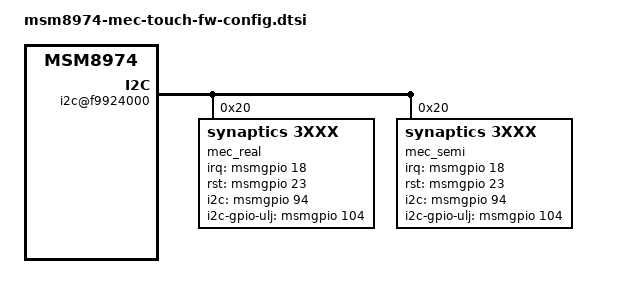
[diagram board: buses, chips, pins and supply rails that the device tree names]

/* Copyright (c) 2013, The Linux Foundation. All rights reserved.
 *
 * This program is free software; you can redistribute it and/or modify
 * it under the terms of the GNU General Public License version 2 and
 * only version 2 as published by the Free Software Foundation.
 *
 * This program is distributed in the hope that it will be useful,
 * but WITHOUT ANY WARRANTY; without even the implied warranty of
 * MERCHANTABILITY or FITNESS FOR A PARTICULAR PURPOSE.  See the
 * GNU General Public License for more details.
 */

&soc {
	i2c@f9924000 {
		mec_real@20 {
			compatible               = "synaptics,3xxx";
			reg                      = <0x20>;
			interrupt-parent         = <&msmgpio>;
			interrupts               = <18 0x2>;
			synaptics,display-coords = <0 1080 0 1920>;
			synaptics,irq-gpio       = <&msmgpio 18 0x00>;
			synaptics,rst-gpio       = <&msmgpio 23 0x00>;
			synaptics,i2c-gpio       = <&msmgpio 94 0x00>;
			synaptics,i2c-gpio-ulj   = <&msmgpio 104 0x00>;
			synaptics,i2c_err_hlr    = <1>;
			tw_pin_mask              = <0x05>;
			report_type              = <1>;
			virtualkey0              = <&syn_vk>;
			virtualkey1              = <&syn_vk_1>;
			virtualkey2              = <&syn_vk_t6>;

			config_3508_0key_metmm_1 {
				default_cfg   = <1>;
				pr_number     = <1606383>;
				sensor_id     = <0x0>;
				syn,pl-coords = <0 1620 0 2880>;
				vkey_setting  = <0>;
				config = [
					4D 45 43 01 00 3F 03 1E
					05 0E 54 06 40 0B 08 43
					87 41 00 00 00 00 0F 1B
					01 1E 05 EF 32 E0 02 28
					10 02 11 01 E7 BD DC C5
					89 80 C4 C4 05 03 12 1E
					8C 0F 0A 20 00 01 01 07
					04 04 0A C0 19 64 26 26
					80 80 00 00 1E 03 06 14
					28 10 40 10 04 04 57 1C
					00 15 40 32 50 00 00 00
					00 4C 04 6C 07 3C 32 00
					00 00 00 4C 04 6C 07 1E
					05 1E 04 0A 04 0A 00 0A
					04 04 00 00 00 01 05 0A
					10 00 00 00 14 03 06 0F
					0A 00 4B 00 FF 00 06 01
					80 04 1B 00 00 00 64 00
					00 00 BE 4B 96 00 00 C0
					80 00 10 0A 18 00 7D 00
					02 00 00 90 01 02 00 03
					03 07 07 03 96 00 08 0C
					01 04 04 39 00 19 00 00
					00 02 00 01 29 84 37 00
					18 00 01 00 02 00 01 2A
					04 36 00 17 00 02 00 02
					00 01 2B 84 35 00 17 00
					03 00 02 00 01 2C 04 34
					00 17 00 04 00 02 00 01
					2D 83 33 00 16 00 05 00
					05 00 02 26 83 32 00 16
					00 06 00 05 00 02 27 03
					31 00 15 00 07 00 05 00
					02 28 08 08 08 08 08 08
					08 08 08 08 08 08 08 08
					08 00 00 00 00 00 00 00
					00 00 00 00 00 00 00 00
					00 00 00 00 00 00 00 00
					00 00 00 00 00 00 00 00
					00 00 00 00 00 00 00 00
					00 00 00 00 00 00 00 00
					00 00 00 00 00 00 00 00
					00 00 00 00 00 00 0F 0F
					06 00 07 0F 0F 06 00 07
					1D 00 05 00 A6 00 14 64
					05 00 00 07 07 00 00 07
					07 00 1B 28 05 01 00 22
					20 00 05 00 00 02 23 2D
					2D A0 00 A0 00 00 00 00
					00 00 00 00 00 00 00 00
					00 00 FF FF FF FF FF FF
					FF FF 51 51 51 51 CD 0D
					04 83 10 10 10 10 05 20
					1F 1E 1D 1C 1B 1A 18 17
					16 15 14 13 12 11 FF FF
					FF FF FF FF FF 00 01 02
					03 04 05 06 07 08 09 0A
					0B 0C 0D 33 32 31 30 2F
					2E 2D 2C 2B 2A 29 28 27
					FF FF FF FF FF 00 10 00
					10 00 10 00 10 80 80 80
					80 80 80 80 80 80 80 80
					80 80 80 80 80 80 80 80
					80 80 80 80 80 80 80 80
					80 80 80 80 80 80 80 80
					80 80 80 80 80 80 80 80
					80 80 80 80 80 80 80 80
					80 80 80 00 10 00 10 00
					10 00 10 00 00 21 22 FF
					FF 0E 26 35 FF
					];
			};

			config_3508_0key_metss_1 {
				default_cfg   = <1>;
				pr_number     = <1606383>;
				sensor_id     = <0x1>;
				syn,pl-coords = <0 1620 0 2880>;
				vkey_setting  = <0>;
				config = [
					4D 45 43 01 00 3F 03 1E
					05 0E 54 06 40 0B 08 43
					87 41 00 00 00 00 0F 1B
					01 1E 05 EF 32 E0 02 28
					10 02 11 01 E7 BD DC C5
					89 80 C4 C4 05 03 12 1E
					8C 0F 0A 20 00 01 01 07
					04 04 0A C0 19 64 26 26
					80 80 00 00 1E 03 06 14
					28 10 40 10 04 04 57 1C
					00 15 40 32 50 00 00 00
					00 4C 04 6C 07 3C 32 00
					00 00 00 4C 04 6C 07 1E
					05 1E 04 0A 04 0A 00 0A
					04 04 00 00 00 01 05 0A
					10 00 00 00 14 03 06 0F
					0A 00 4B 00 FF 00 06 01
					80 04 1B 00 00 00 64 00
					00 00 BE 4B 96 00 00 C0
					80 00 10 0A 18 00 7D 00
					02 00 00 90 01 02 00 03
					03 07 07 03 96 00 08 0C
					01 04 04 39 00 19 00 00
					00 02 00 01 29 84 37 00
					18 00 01 00 02 00 01 2A
					04 36 00 17 00 02 00 02
					00 01 2B 84 35 00 17 00
					03 00 02 00 01 2C 04 34
					00 17 00 04 00 02 00 01
					2D 83 33 00 16 00 05 00
					05 00 02 26 83 32 00 16
					00 06 00 05 00 02 27 03
					31 00 15 00 07 00 05 00
					02 28 08 08 08 08 08 08
					08 08 08 08 08 08 08 08
					08 00 00 00 00 00 00 00
					00 00 00 00 00 00 00 00
					00 00 00 00 00 00 00 00
					00 00 00 00 00 00 00 00
					00 00 00 00 00 00 00 00
					00 00 00 00 00 00 00 00
					00 00 00 00 00 00 00 00
					00 00 00 00 00 00 0F 0F
					06 00 07 0F 0F 06 00 07
					1D 00 05 00 A6 00 14 64
					05 00 00 07 07 00 00 07
					07 00 1B 28 05 01 00 22
					20 00 05 00 00 02 23 2D
					2D A0 00 A0 00 00 00 00
					00 00 00 00 00 00 00 00
					00 00 FF FF FF FF FF FF
					FF FF 51 51 51 51 CD 0D
					04 83 10 10 10 10 05 20
					1F 1E 1D 1C 1B 1A 18 17
					16 15 14 13 12 11 FF FF
					FF FF FF FF FF 00 01 02
					03 04 05 06 07 08 09 0A
					0B 0C 0D 33 32 31 30 2F
					2E 2D 2C 2B 2A 29 28 27
					FF FF FF FF FF 00 10 00
					10 00 10 00 10 80 80 80
					80 80 80 80 80 80 80 80
					80 80 80 80 80 80 80 80
					80 80 80 80 80 80 80 80
					80 80 80 80 80 80 80 80
					80 80 80 80 80 80 80 80
					80 80 80 80 80 80 80 80
					80 80 80 00 10 00 10 00
					10 00 10 00 00 21 22 FF
					FF 0E 26 35 FF
					];
			};



			config_3508_0key_metm_1 {
				default_cfg   = <1>;
				pr_number     = <1582320>;
				sensor_id     = <0x0>;
				syn,pl-coords = <0 1620 0 2880>;
				vkey_setting  = <0>;
				config = [
					4D 45 43 01 00 3F 03 1E
					05 0E 54 06 40 0B 08 43
					87 41 00 00 00 00 0F 1B
					01 1E 05 EF 32 E0 02 28
					10 02 11 01 E7 BD DC C5
					89 80 C4 C4 05 03 12 1E
					8C 0F 0A 20 00 01 01 07
					04 04 0A C0 19 64 26 26
					80 80 00 00 1E 03 06 14
					28 10 40 10 04 04 57 1C
					00 15 40 32 50 00 00 00
					00 4C 04 6C 07 3C 32 00
					00 00 00 4C 04 6C 07 1E
					05 1E 04 0A 04 0A 00 0A
					04 04 00 00 00 01 05 0A
					10 00 00 00 14 03 06 0F
					0A 00 4B 00 FF 00 06 01
					80 04 1B 00 00 00 64 00
					00 00 BE 4B 96 00 00 C0
					80 00 10 0A 18 00 7D 00
					02 00 00 90 01 02 00 03
					03 07 07 03 96 00 08 0C
					01 04 04 39 00 19 00 00
					00 02 00 01 29 84 37 00
					18 00 01 00 02 00 01 2A
					04 36 00 17 00 02 00 02
					00 01 2B 84 35 00 17 00
					03 00 02 00 01 2C 04 34
					00 17 00 04 00 02 00 01
					2D 83 33 00 16 00 05 00
					05 00 02 26 83 32 00 16
					00 06 00 05 00 02 27 03
					31 00 15 00 07 00 05 00
					02 28 08 08 08 08 08 08
					08 08 08 08 08 08 08 08
					08 00 00 00 00 00 00 00
					00 00 00 00 00 00 00 00
					00 00 00 00 00 00 00 00
					00 00 00 00 00 00 00 00
					00 00 00 00 00 00 00 00
					00 00 00 00 00 00 00 00
					00 00 00 00 00 00 00 00
					00 00 00 00 00 00 0F 0F
					06 00 07 0F 0F 06 00 07
					1D 00 05 00 A6 00 14 64
					05 00 00 07 07 00 00 07
					07 00 1B 28 05 01 00 22
					20 00 05 00 00 02 23 2D
					2D A0 00 A0 00 00 00 00
					00 00 00 00 00 00 00 00
					00 00 FF FF FF FF FF FF
					FF FF 51 51 51 51 CD 0D
					04 83 10 10 10 10 05 20
					1F 1E 1D 1C 1B 1A 18 17
					16 15 14 13 12 11 FF FF
					FF FF FF FF FF 00 01 02
					03 04 05 06 07 08 09 0A
					0B 0C 0D 33 32 31 30 2F
					2E 2D 2C 2B 2A 29 28 27
					FF FF FF FF FF 00 10 00
					10 00 10 00 10 80 80 80
					80 80 80 80 80 80 80 80
					80 80 80 80 80 80 80 80
					80 80 80 80 80 80 80 80
					80 80 80 80 80 80 80 80
					80 80 80 80 80 80 80 80
					80 80 80 80 80 80 80 80
					80 80 80 00 10 00 10 00
					10 00 10 00 00 21 22 FF
					FF 0E 26 35 FF
				];
			};

			config_3508_0key_mets_1 {
				default_cfg   = <1>;
				pr_number     = <1582320>;
				sensor_id     = <0x1>;
				syn,pl-coords = <0 1620 0 2880>;
				vkey_setting  = <0>;
				config = [
					4D 45 43 01 00 3F 03 1E
					05 0E 54 06 40 0B 08 43
					87 41 00 00 00 00 0F 1B
					01 1E 05 EF 32 E0 02 28
					10 02 11 01 E7 BD DC C5
					89 80 C4 C4 05 03 12 1E
					8C 0F 0A 20 00 01 01 07
					04 04 0A C0 19 64 26 26
					80 80 00 00 1E 03 06 14
					28 10 40 10 04 04 57 1C
					00 15 40 32 50 00 00 00
					00 4C 04 6C 07 3C 32 00
					00 00 00 4C 04 6C 07 1E
					05 1E 04 0A 04 0A 00 0A
					04 04 00 00 00 01 05 0A
					10 00 00 00 14 03 06 0F
					0A 00 4B 00 FF 00 06 01
					80 04 1B 00 00 00 64 00
					00 00 BE 4B 96 00 00 C0
					80 00 10 0A 18 00 7D 00
					02 00 00 90 01 02 00 03
					03 07 07 03 96 00 08 0C
					01 04 04 39 00 19 00 00
					00 02 00 01 29 84 37 00
					18 00 01 00 02 00 01 2A
					04 36 00 17 00 02 00 02
					00 01 2B 84 35 00 17 00
					03 00 02 00 01 2C 04 34
					00 17 00 04 00 02 00 01
					2D 83 33 00 16 00 05 00
					05 00 02 26 83 32 00 16
					00 06 00 05 00 02 27 03
					31 00 15 00 07 00 05 00
					02 28 08 08 08 08 08 08
					08 08 08 08 08 08 08 08
					08 00 00 00 00 00 00 00
					00 00 00 00 00 00 00 00
					00 00 00 00 00 00 00 00
					00 00 00 00 00 00 00 00
					00 00 00 00 00 00 00 00
					00 00 00 00 00 00 00 00
					00 00 00 00 00 00 00 00
					00 00 00 00 00 00 0F 0F
					06 00 07 0F 0F 06 00 07
					1D 00 05 00 A6 00 14 64
					05 00 00 07 07 00 00 07
					07 00 1B 28 05 01 00 22
					20 00 05 00 00 02 23 2D
					2D A0 00 A0 00 00 00 00
					00 00 00 00 00 00 00 00
					00 00 FF FF FF FF FF FF
					FF FF 51 51 51 51 CD 0D
					04 83 10 10 10 10 05 20
					1F 1E 1D 1C 1B 1A 18 17
					16 15 14 13 12 11 FF FF
					FF FF FF FF FF 00 01 02
					03 04 05 06 07 08 09 0A
					0B 0C 0D 33 32 31 30 2F
					2E 2D 2C 2B 2A 29 28 27
					FF FF FF FF FF 00 10 00
					10 00 10 00 10 80 80 80
					80 80 80 80 80 80 80 80
					80 80 80 80 80 80 80 80
					80 80 80 80 80 80 80 80
					80 80 80 80 80 80 80 80
					80 80 80 80 80 80 80 80
					80 80 80 80 80 80 80 80
					80 80 80 00 10 00 10 00
					10 00 10 00 00 21 22 FF
					FF 0E 26 35 FF
				];
			};

			config_3508_0key_tsxm_2 {
				default_cfg   = <1>;
				pr_number     = <1543518>;
				sensor_id     = <0x4>;
				syn,pl-coords = <0 1620 0 2880>;
				vkey_setting  = <0>;
				config = [
					54 53 58 00 00 3F 03 1E
					05 0E 54 06 40 0B 4D 41
					48 3B 00 00 00 00 11 1B
					01 1E 05 EF 32 E0 02 28
					19 01 1D 00 48 C9 05 E4
					89 80 C4 C4 05 03 12 1E
					5A 0F 0A 20 00 01 01 07
					04 04 0A C0 19 64 26 26
					80 80 00 00 1E 03 06 14
					28 10 40 10 04 04 2D 1C
					00 15 40 32 50 00 00 00
					00 4C 04 6C 07 3C 32 00
					00 00 00 4C 04 6C 07 1E
					05 1E 04 0A 04 0A 00 0A
					04 04 00 00 00 01 05 0A
					10 00 00 00 14 03 06 0F
					0A 00 4B 00 FF 00 04 01
					80 04 1B 00 00 00 64 00
					00 00 BE 4B 96 00 00 C0
					80 00 10 0A 18 00 7D 00
					02 00 00 90 01 02 00 06
					06 07 07 00 96 00 08 0C
					01 04 03 2A 00 13 00 00
					00 03 00 01 25 03 29 00
					12 00 02 00 03 00 01 27
					03 28 00 11 00 04 00 03
					00 01 28 02 26 00 11 00
					06 00 03 00 01 29 02 25
					00 10 00 08 00 07 00 02
					25 02 24 00 10 00 0A 00
					07 00 02 26 02 23 00 0F
					00 0C 00 07 00 02 27 02
					22 00 0F 00 0E 00 04 00
					01 23 0F 0F 0F 0F 0F 0F
					0F 0F 0F 0F 0F 0F 0F 0F
					0F 0F 00 00 00 00 00 00
					00 00 00 00 00 00 00 00
					00 00 00 00 00 00 00 00
					00 00 00 00 00 00 00 00
					00 00 00 00 00 00 00 00
					00 00 00 00 00 00 00 00
					00 00 00 00 00 00 00 00
					00 00 00 00 00 00 0E 0E
					02 00 04 0E 0E 02 00 04
					2B 00 05 00 A6 00 14 64
					05 04 04 03 03 04 04 03
					03 00 1B 28 05 01 00 22
					20 00 05 00 00 00 14 28
					28 A0 00 A0 00 00 00 00
					00 00 00 00 00 00 00 00
					00 00 FF FF FF FF FF FF
					FF FF 51 51 51 51 CD 0D
					04 83 10 10 10 10 05 22
					21 20 1F 1E 1D 1C 1B 1A
					19 18 17 16 15 14 13 12
					FF FF FF FF FF 00 01 02
					03 04 05 06 07 08 09 0A
					0B 0C 0D 0E 26 33 32 31
					30 2F 2E 2D 2C 2B 2A 29
					FF FF FF FF FF 00 10 00
					10 00 10 00 10 80 80 80
					80 80 80 80 80 80 80 80
					80 80 80 80 80 80 80 80
					80 80 80 80 80 80 80 80
					80 80 80 80 80 80 80 80
					80 80 80 80 80 80 80 80
					80 80 80 80 80 80 80 80
					80 80 80 00 10 00 10 00
					10 00 10 00 00 FF FF FF
					FF FF FF FF FF
				];
			};

			config_3508_0key_tsms_2 {
				default_cfg   = <1>;
				pr_number     = <1543518>;
				sensor_id     = <0x5>;
				syn,pl-coords = <0 1620 0 2880>;
				vkey_setting  = <0>;
				config = [
					54 53 58 00 00 3F 03 1E
					05 0E 54 06 40 0B 4D 41
					48 3B 00 00 00 00 11 1B
					01 1E 05 EF 32 E0 02 28
					19 01 1D 00 48 C9 05 E4
					89 80 C4 C4 05 03 12 1E
					5A 0F 0A 20 00 01 01 07
					04 04 0A C0 19 64 26 26
					80 80 00 00 1E 03 06 14
					28 10 40 10 04 04 2D 1C
					00 15 40 32 50 00 00 00
					00 4C 04 6C 07 3C 32 00
					00 00 00 4C 04 6C 07 1E
					05 1E 04 0A 04 0A 00 0A
					04 04 00 00 00 01 05 0A
					10 00 00 00 14 03 06 0F
					0A 00 4B 00 FF 00 04 01
					80 04 1B 00 00 00 64 00
					00 00 BE 4B 96 00 00 C0
					80 00 10 0A 18 00 7D 00
					02 00 00 90 01 02 00 06
					06 07 07 00 96 00 08 0C
					01 04 03 2A 00 13 00 00
					00 03 00 01 25 03 29 00
					12 00 02 00 03 00 01 27
					03 28 00 11 00 04 00 03
					00 01 28 02 26 00 11 00
					06 00 03 00 01 29 02 25
					00 10 00 08 00 07 00 02
					25 02 24 00 10 00 0A 00
					07 00 02 26 02 23 00 0F
					00 0C 00 07 00 02 27 02
					22 00 0F 00 0E 00 04 00
					01 23 0F 0F 0F 0F 0F 0F
					0F 0F 0F 0F 0F 0F 0F 0F
					0F 0F 00 00 00 00 00 00
					00 00 00 00 00 00 00 00
					00 00 00 00 00 00 00 00
					00 00 00 00 00 00 00 00
					00 00 00 00 00 00 00 00
					00 00 00 00 00 00 00 00
					00 00 00 00 00 00 00 00
					00 00 00 00 00 00 0E 0E
					02 00 04 0E 0E 02 00 04
					2B 00 05 00 A6 00 14 64
					05 04 04 03 03 04 04 03
					03 00 1B 28 05 01 00 22
					20 00 05 00 00 00 14 28
					28 A0 00 A0 00 00 00 00
					00 00 00 00 00 00 00 00
					00 00 FF FF FF FF FF FF
					FF FF 51 51 51 51 CD 0D
					04 83 10 10 10 10 05 22
					21 20 1F 1E 1D 1C 1B 1A
					19 18 17 16 15 14 13 12
					FF FF FF FF FF 00 01 02
					03 04 05 06 07 08 09 0A
					0B 0C 0D 0E 26 33 32 31
					30 2F 2E 2D 2C 2B 2A 29
					FF FF FF FF FF 00 10 00
					10 00 10 00 10 80 80 80
					80 80 80 80 80 80 80 80
					80 80 80 80 80 80 80 80
					80 80 80 80 80 80 80 80
					80 80 80 80 80 80 80 80
					80 80 80 80 80 80 80 80
					80 80 80 80 80 80 80 80
					80 80 80 00 10 00 10 00
					10 00 10 00 00 FF FF FF
					FF FF FF FF FF
				];
			};

			config_3508_2key_metm_1 {
				default_cfg   = <1>;
				pr_number     = <1543518>;
				sensor_id     = <0x0>;
				syn,pl-coords = <0 1620 0 2880>;
				vkey_setting  = <0>;
				config = [
					4D 45 54 31 00 3F 03 1E
					05 0E 54 06 40 0B 23 43
					5A 41 00 00 00 00 0F 1B
					01 1E 05 EF 32 DD 02 50
					19 01 1D 00 48 C9 05 E4
					89 80 C4 C4 05 03 12 1E
					5A 0F 0A 20 00 01 01 07
					04 04 0A C0 19 64 26 26
					80 80 00 00 1E 03 06 14
					28 10 40 10 04 04 2D 1C
					00 15 40 32 50 32 00 00
					00 00 4C 04 6C 07 3C 32
					00 00 00 00 4C 04 6C 07
					1E 05 1E 04 0A 04 0A 00
					0A 04 04 00 00 00 01 05
					0A 00 00 00 4B FF 00 04
					01 80 04 1B 00 00 00 64
					00 00 00 BE 4B 96 00 00
					C0 80 00 10 0A 18 00 7D
					00 02 00 00 90 01 02 00
					06 06 07 07 00 96 00 08
					0C 01 04 03 29 00 13 00
					00 00 03 00 01 25 03 28
					00 12 00 02 00 03 00 01
					27 82 26 00 11 00 04 00
					03 00 01 28 02 25 00 11
					00 06 00 03 00 01 29 02
					24 00 10 00 08 00 07 00
					02 25 02 23 00 10 00 0A
					00 07 00 02 26 02 22 00
					0F 00 0C 00 07 00 02 27
					02 21 00 0F 00 0E 00 04
					00 01 23 0E 0F 0F 0F 0F
					0F 0E 0F 0F 0F 0F 0F 0F
					0F 0F 0F 0C 00 00 00 00
					00 00 00 00 00 00 00 00
					00 00 00 00 00 00 00 00
					00 00 00 00 00 00 00 00
					00 00 00 00 00 00 00 00
					00 00 00 00 00 00 00 00
					00 00 00 00 00 00 00 00
					00 00 00 00 00 00 00 0E
					0E 02 00 04 0E 0E 02 00
					04 2B 00 05 00 A6 00 14
					64 05 04 04 03 03 04 04
					03 03 00 1B 28 05 01 00
					22 20 00 05 00 00 00 14
					2D 2D A0 00 A0 00 00 00
					00 FF FF FF FF FF FF FF
					FF A1 A1 51 51 CD 0D 04
					83 10 10 10 10 05 1F 1E
					1D 1C 1B 1A 19 18 17 16
					15 14 13 12 11 FF FF FF
					FF FF FF FF 00 01 02 03
					04 05 06 07 08 09 0A 0B
					0C 0D 33 32 31 30 2F 2E
					2D 2C 2B 2A 29 28 27 FF
					FF FF FF FF 00 10 00 10
					00 10 00 10 80 80 80 80
					80 80 80 80 80 80 80 80
					80 80 80 80 80 80 80 80
					80 80 80 80 80 80 80 80
					80 80 80 80 80 80 80 80
					80 80 80 80 80 80 80 80
					80 80 80 80 80 80 80 80
					80 80 00 10 00 10 00 10
					00 10
				];
			};

			config_3508_2key_mets_1 {
				default_cfg   = <1>;
				pr_number     = <1543518>;
				sensor_id     = <0x1>;
				syn,pl-coords = <0 1620 0 2880>;
				vkey_setting  = <0>;
				config = [
					4D 45 54 31 00 3F 03 1E
					05 0E 54 06 40 0B 23 43
					5A 41 00 00 00 00 0F 1B
					01 1E 05 EF 32 DD 02 50
					19 01 1D 00 48 C9 05 E4
					89 80 C4 C4 05 03 12 1E
					5A 0F 0A 20 00 01 01 07
					04 04 0A C0 19 64 26 26
					80 80 00 00 1E 03 06 14
					28 10 40 10 04 04 2D 1C
					00 15 40 32 50 32 00 00
					00 00 4C 04 6C 07 3C 32
					00 00 00 00 4C 04 6C 07
					1E 05 1E 04 0A 04 0A 00
					0A 04 04 00 00 00 01 05
					0A 00 00 00 4B FF 00 04
					01 80 04 1B 00 00 00 64
					00 00 00 BE 4B 96 00 00
					C0 80 00 10 0A 18 00 7D
					00 02 00 00 90 01 02 00
					06 06 07 07 00 96 00 08
					0C 01 04 03 29 00 13 00
					00 00 03 00 01 25 03 28
					00 12 00 02 00 03 00 01
					27 82 26 00 11 00 04 00
					03 00 01 28 02 25 00 11
					00 06 00 03 00 01 29 02
					24 00 10 00 08 00 07 00
					02 25 02 23 00 10 00 0A
					00 07 00 02 26 02 22 00
					0F 00 0C 00 07 00 02 27
					02 21 00 0F 00 0E 00 04
					00 01 23 0E 0F 0F 0F 0F
					0F 0E 0F 0F 0F 0F 0F 0F
					0F 0F 0F 0C 00 00 00 00
					00 00 00 00 00 00 00 00
					00 00 00 00 00 00 00 00
					00 00 00 00 00 00 00 00
					00 00 00 00 00 00 00 00
					00 00 00 00 00 00 00 00
					00 00 00 00 00 00 00 00
					00 00 00 00 00 00 00 0E
					0E 02 00 04 0E 0E 02 00
					04 2B 00 05 00 A6 00 14
					64 05 04 04 03 03 04 04
					03 03 00 1B 28 05 01 00
					22 20 00 05 00 00 00 14
					2D 2D A0 00 A0 00 00 00
					00 FF FF FF FF FF FF FF
					FF A1 A1 51 51 CD 0D 04
					83 10 10 10 10 05 1F 1E
					1D 1C 1B 1A 19 18 17 16
					15 14 13 12 11 FF FF FF
					FF FF FF FF 00 01 02 03
					04 05 06 07 08 09 0A 0B
					0C 0D 33 32 31 30 2F 2E
					2D 2C 2B 2A 29 28 27 FF
					FF FF FF FF 00 10 00 10
					00 10 00 10 80 80 80 80
					80 80 80 80 80 80 80 80
					80 80 80 80 80 80 80 80
					80 80 80 80 80 80 80 80
					80 80 80 80 80 80 80 80
					80 80 80 80 80 80 80 80
					80 80 80 80 80 80 80 80
					80 80 00 10 00 10 00 10
					00 10
				];
			};

			config_3508_0key_tsxm_1 {
				default_cfg   = <1>;
				pr_number     = <1543518>;
				sensor_id     = <0x4>;
				syn,pl-coords = <0 1620 0 2880>;
				vkey_setting  = <0>;
				config = [
					54 53 58 31 00 3F 03 1E
					05 0E 54 06 40 0B 48 3B
					66 41 00 00 00 00 11 1B
					01 1E 05 EF 32 DD 02 50
					19 01 1D 00 48 C9 05 E4
					89 80 C4 C4 05 03 12 1E
					5A 0F 0A 20 00 01 01 07
					04 04 0A C0 19 64 26 26
					80 80 00 00 1E 03 06 14
					28 10 40 10 04 04 2D 1C
					00 15 40 32 50 32 00 00
					00 00 4C 04 6C 07 3C 32
					00 00 00 00 4C 04 6C 07
					1E 05 1E 04 0A 04 0A 00
					0A 04 04 00 00 00 01 05
					0A 00 00 00 4B FF 00 04
					01 80 04 1B 00 00 00 64
					00 00 00 BE 4B 96 00 00
					C0 80 00 10 0A 18 00 7D
					00 02 00 00 90 01 02 00
					06 06 07 07 00 96 00 08
					0C 01 04 03 29 00 13 00
					00 00 03 00 01 25 03 28
					00 12 00 02 00 03 00 01
					27 82 26 00 11 00 04 00
					03 00 01 28 02 25 00 11
					00 06 00 03 00 01 29 02
					24 00 10 00 08 00 07 00
					02 25 02 23 00 10 00 0A
					00 07 00 02 26 02 22 00
					0F 00 0C 00 07 00 02 27
					02 21 00 0F 00 0E 00 04
					00 01 23 0E 0F 0F 0F 0F
					0F 0E 0F 0F 0F 0F 0F 0F
					0F 0F 0F 0C 00 00 00 00
					00 00 00 00 00 00 00 00
					00 00 00 00 00 00 00 00
					00 00 00 00 00 00 00 00
					00 00 00 00 00 00 00 00
					00 00 00 00 00 00 00 00
					00 00 00 00 00 00 00 00
					00 00 00 00 00 00 00 0E
					0E 02 00 04 0E 0E 02 00
					04 2B 00 05 00 A6 00 14
					64 05 04 04 03 03 04 04
					03 03 00 1B 28 05 01 00
					22 20 00 05 00 00 00 14
					2D 2D A0 00 A0 00 00 00
					00 FF FF FF FF FF FF FF
					FF A1 A1 51 51 CD 0D 04
					83 10 10 10 10 05 22 21
					20 1F 1E 1D 1C 1B 1A 19
					18 17 16 15 14 13 12 FF
					FF FF FF FF 00 01 02 03
					04 05 06 07 08 09 0A 0B
					0C 0D 0E 26 33 32 31 30
					2F 2E 2D 2C 2B 2A 29 FF
					FF FF FF FF 00 10 00 10
					00 10 00 10 80 80 80 80
					80 80 80 80 80 80 80 80
					80 80 80 80 80 80 80 80
					80 80 80 80 80 80 80 80
					80 80 80 80 80 80 80 80
					80 80 80 80 80 80 80 80
					80 80 80 80 80 80 80 80
					80 80 00 10 00 10 00 10
					00 10
				];
			};

			config_3508_0key_tsms_1 {
				default_cfg   = <1>;
				pr_number     = <1543518>;
				sensor_id     = <0x5>;
				syn,pl-coords = <0 1620 0 2880>;
				vkey_setting  = <0>;
				config = [
					54 53 58 31 00 3F 03 1E
					05 0E 54 06 40 0B 48 3B
					66 41 00 00 00 00 11 1B
					01 1E 05 EF 32 DD 02 50
					19 01 1D 00 48 C9 05 E4
					89 80 C4 C4 05 03 12 1E
					5A 0F 0A 20 00 01 01 07
					04 04 0A C0 19 64 26 26
					80 80 00 00 1E 03 06 14
					28 10 40 10 04 04 2D 1C
					00 15 40 32 50 32 00 00
					00 00 4C 04 6C 07 3C 32
					00 00 00 00 4C 04 6C 07
					1E 05 1E 04 0A 04 0A 00
					0A 04 04 00 00 00 01 05
					0A 00 00 00 4B FF 00 04
					01 80 04 1B 00 00 00 64
					00 00 00 BE 4B 96 00 00
					C0 80 00 10 0A 18 00 7D
					00 02 00 00 90 01 02 00
					06 06 07 07 00 96 00 08
					0C 01 04 03 29 00 13 00
					00 00 03 00 01 25 03 28
					00 12 00 02 00 03 00 01
					27 82 26 00 11 00 04 00
					03 00 01 28 02 25 00 11
					00 06 00 03 00 01 29 02
					24 00 10 00 08 00 07 00
					02 25 02 23 00 10 00 0A
					00 07 00 02 26 02 22 00
					0F 00 0C 00 07 00 02 27
					02 21 00 0F 00 0E 00 04
					00 01 23 0E 0F 0F 0F 0F
					0F 0E 0F 0F 0F 0F 0F 0F
					0F 0F 0F 0C 00 00 00 00
					00 00 00 00 00 00 00 00
					00 00 00 00 00 00 00 00
					00 00 00 00 00 00 00 00
					00 00 00 00 00 00 00 00
					00 00 00 00 00 00 00 00
					00 00 00 00 00 00 00 00
					00 00 00 00 00 00 00 0E
					0E 02 00 04 0E 0E 02 00
					04 2B 00 05 00 A6 00 14
					64 05 04 04 03 03 04 04
					03 03 00 1B 28 05 01 00
					22 20 00 05 00 00 00 14
					2D 2D A0 00 A0 00 00 00
					00 FF FF FF FF FF FF FF
					FF A1 A1 51 51 CD 0D 04
					83 10 10 10 10 05 22 21
					20 1F 1E 1D 1C 1B 1A 19
					18 17 16 15 14 13 12 FF
					FF FF FF FF 00 01 02 03
					04 05 06 07 08 09 0A 0B
					0C 0D 0E 26 33 32 31 30
					2F 2E 2D 2C 2B 2A 29 FF
					FF FF FF FF 00 10 00 10
					00 10 00 10 80 80 80 80
					80 80 80 80 80 80 80 80
					80 80 80 80 80 80 80 80
					80 80 80 80 80 80 80 80
					80 80 80 80 80 80 80 80
					80 80 80 80 80 80 80 80
					80 80 80 80 80 80 80 80
					80 80 00 10 00 10 00 10
					00 10
				];
			};

			config_t6m_1 {
				default_cfg   = <1>;
				pr_number     = <1501819>;
				sensor_id     = <0x04>;
				syn,pl-coords = <50 1050 0 1800>;
				vkey_setting  = <2>;
				config = [
					00 00 00 02 04 3F 03 1E
					05 0E 4C 04 6C 07 00 40
					00 40 00 00 00 00 11 1D
					01 1E 05 F5 28 1E 05 28
					30 00 30 00 F0 D2 F0 D2
					89 80 C4 C4 05 03 05 0F
					80 0F 0A 20 00 01 01 07
					04 04 0A C0 19 64 26 26
					80 80 00 00 80 19 01 40
					40 32 50 80 32 00 00 00
					00 4C 04 6C 07 3C 32 00
					00 00 00 4C 04 6C 07 1E
					05 00 00 00 00 05 0A 00
					03 FF 00 FA 00 80 04 1B
					00 00 00 FF FF FF FF FF
					FF FF FF 00 C0 80 00 10
					0A 18 00 71 00 FF FF 00
					FF FF FF FF 03 03 07 07
					01 FF FF 01 04 05 4A 00
					4A 00 00 00 02 00 01 3E
					85 4A 00 4A 00 00 00 02
					00 01 3E 85 4A 00 4A 00
					00 00 02 00 01 3E 85 4A
					00 4A 00 00 00 02 00 01
					3E 85 4A 00 4A 00 00 00
					02 00 01 3E 85 4A 00 4A
					00 00 00 02 00 01 3E 85
					4A 00 4A 00 00 00 02 00
					01 3E 85 4A 00 4A 00 00
					00 02 00 01 3E 02 02 02
					02 02 02 02 02 02 02 02
					02 02 02 02 02 02 02 02
					02 02 02 26 00 05 00 A6
					00 14 64 05 00 1B 00 11
					0A 32 0A 32 14 20 46 00
					00 00 FF FF FF FF FF FF
					FF FF 51 51 51 51 CD 0D
					04 83 10 10 10 10 05 22
					21 20 1F 1E 1D 1C 1B 1A
					19 18 17 16 15 14 13 12
					FF FF FF FF FF 00 01 02
					03 04 05 06 07 08 09 0A
					0B 0C 0D 0E 26 33 32 31
					30 2F 2E 2D 2C 2B 2A 29
					28 27 FF FF FF 00 10 00
					10 00 10 00 10 80 80 80
					80 80 80 80 80 80 80 80
					80 80 80 80 80 80 80 80
					80 80 80 80 80 80 80 80
					80 80 80 80 80 80 80 80
					80 80 80 80 80 80 80 80
					80 80 80 80 80 80 80 80
					80 80 80 00 10 00 10 00
					10 00 10
				];
			};

			config_t6s_1 {
				default_cfg   = <1>;
				pr_number     = <1501819>;
				sensor_id     = <0x05>;
				syn,pl-coords = <50 1050 0 1800>;
				vkey_setting  = <2>;
				config = [
					00 00 00 02 04 3F 03 1E
					05 0E 4C 04 6C 07 00 40
					00 40 00 00 00 00 11 1D
					01 1E 05 F5 28 1E 05 28
					30 00 30 00 F0 D2 F0 D2
					89 80 C4 C4 05 03 05 0F
					80 0F 0A 20 00 01 01 07
					04 04 0A C0 19 64 26 26
					80 80 00 00 80 19 01 40
					40 32 50 80 32 00 00 00
					00 4C 04 6C 07 3C 32 00
					00 00 00 4C 04 6C 07 1E
					05 00 00 00 00 05 0A 00
					03 FF 00 FA 00 80 04 1B
					00 00 00 FF FF FF FF FF
					FF FF FF 00 C0 80 00 10
					0A 18 00 71 00 FF FF 00
					FF FF FF FF 03 03 07 07
					01 FF FF 01 04 05 4A 00
					4A 00 00 00 02 00 01 3E
					85 4A 00 4A 00 00 00 02
					00 01 3E 85 4A 00 4A 00
					00 00 02 00 01 3E 85 4A
					00 4A 00 00 00 02 00 01
					3E 85 4A 00 4A 00 00 00
					02 00 01 3E 85 4A 00 4A
					00 00 00 02 00 01 3E 85
					4A 00 4A 00 00 00 02 00
					01 3E 85 4A 00 4A 00 00
					00 02 00 01 3E 02 02 02
					02 02 02 02 02 02 02 02
					02 02 02 02 02 02 02 02
					02 02 02 26 00 05 00 A6
					00 14 64 05 00 1B 00 11
					0A 32 0A 32 14 20 46 00
					00 00 FF FF FF FF FF FF
					FF FF 51 51 51 51 CD 0D
					04 83 10 10 10 10 05 22
					21 20 1F 1E 1D 1C 1B 1A
					19 18 17 16 15 14 13 12
					FF FF FF FF FF 00 01 02
					03 04 05 06 07 08 09 0A
					0B 0C 0D 0E 26 33 32 31
					30 2F 2E 2D 2C 2B 2A 29
					28 27 FF FF FF 00 10 00
					10 00 10 00 10 80 80 80
					80 80 80 80 80 80 80 80
					80 80 80 80 80 80 80 80
					80 80 80 80 80 80 80 80
					80 80 80 80 80 80 80 80
					80 80 80 80 80 80 80 80
					80 80 80 80 80 80 80 80
					80 80 80 00 10 00 10 00
					10 00 10
				];
			};
		};
		mec_semi@20 {
			compatible               = "synaptics,3xxx";
			reg                      = <0x20>;
			interrupt-parent         = <&msmgpio>;
			interrupts               = <18 0x2>;
			synaptics,display-coords = <0 1080 0 1920>;
			synaptics,irq-gpio       = <&msmgpio 18 0x00>;
			synaptics,rst-gpio       = <&msmgpio 23 0x00>;
			synaptics,i2c-gpio       = <&msmgpio 94 0x00>;
			synaptics,i2c-gpio-ulj   = <&msmgpio 104 0x00>;
			synaptics,i2c_err_hlr    = <1>;
			tw_pin_mask              = <0x05>;
			report_type              = <1>;
			virtualkey0              = <&syn_vk>;
			virtualkey1              = <&syn_vk_1>;
			virtualkey2              = <&syn_vk_t6>;

			config_3508_2key_metm_2 {
				default_cfg   = <1>;
				pr_number     = <1582320>;
				sensor_id     = <0x0>;
				syn,pl-coords = <0 1620 0 2880>;
				vkey_setting  = <0>;
				config = [
					4D 45 54 00 00 3F 03 1E
					05 0E 54 06 40 0B 08 43
					87 41 00 00 00 00 0F 1B
					01 1E 05 EF 32 E0 02 28
					19 01 1D 00 48 C9 05 E4
					89 80 C4 C4 05 03 12 1E
					5A 0F 0A 20 00 01 01 07
					04 04 0A C0 19 64 26 26
					80 80 00 00 1E 03 06 14
					28 10 40 10 04 04 2D 1C
					00 15 40 32 50 00 00 00
					00 4C 04 6C 07 3C 32 00
					00 00 00 4C 04 6C 07 1E
					05 1E 04 0A 04 0A 00 0A
					04 04 00 00 00 01 05 0A
					10 00 00 00 14 03 06 0F
					0A 00 4B 00 FF 00 04 01
					80 04 1B 00 00 00 64 00
					00 00 BE 4B 96 00 00 C0
					80 00 10 0A 18 00 7D 00
					02 00 00 90 01 02 00 06
					06 07 07 00 96 00 08 0C
					01 04 03 2A 00 13 00 00
					00 03 00 01 25 03 29 00
					12 00 02 00 03 00 01 27
					03 28 00 11 00 04 00 03
					00 01 28 02 26 00 11 00
					06 00 03 00 01 29 02 25
					00 10 00 08 00 07 00 02
					25 02 24 00 10 00 0A 00
					07 00 02 26 02 23 00 0F
					00 0C 00 07 00 02 27 02
					22 00 0F 00 0E 00 04 00
					01 23 0F 0F 0F 0F 0F 0F
					0F 0F 0F 0F 0F 0F 0F 0F
					0F 0F 00 00 00 00 00 00
					00 00 00 00 00 00 00 00
					00 00 00 00 00 00 00 00
					00 00 00 00 00 00 00 00
					00 00 00 00 00 00 00 00
					00 00 00 00 00 00 00 00
					00 00 00 00 00 00 00 00
					00 00 00 00 00 00 0E 0E
					02 00 04 0E 0E 02 00 04
					2B 00 05 00 A6 00 14 64
					05 04 04 03 03 04 04 03
					03 00 1B 28 05 01 00 22
					20 00 05 00 00 00 14 28
					28 A0 00 A0 00 00 00 00
					00 00 00 00 00 00 00 00
					00 00 FF FF FF FF FF FF
					FF FF 51 51 51 51 CD 0D
					04 83 10 10 10 10 05 1F
					1E 1D 1C 1B 1A 19 18 17
					16 15 14 13 12 11 FF FF
					FF FF FF FF FF 00 01 02
					03 04 05 06 07 08 09 0A
					0B 0C 0D 33 32 31 30 2F
					2E 2D 2C 2B 2A 29 28 27
					FF FF FF FF FF 00 10 00
					10 00 10 00 10 80 80 80
					80 80 80 80 80 80 80 80
					80 80 80 80 80 80 80 80
					80 80 80 80 80 80 80 80
					80 80 80 80 80 80 80 80
					80 80 80 80 80 80 80 80
					80 80 80 80 80 80 80 80
					80 80 80 00 10 00 10 00
					10 00 10 00 00 21 22 FF
					FF 0E 26 35 FF
				];
			};

			config_3508_2key_mets_2 {
				default_cfg   = <1>;
				pr_number     = <1582320>;
				sensor_id     = <0x1>;
				syn,pl-coords = <0 1620 0 2880>;
				vkey_setting  = <0>;
				config = [
					4D 45 54 00 00 3F 03 1E
					05 0E 54 06 40 0B 08 43
					87 41 00 00 00 00 0F 1B
					01 1E 05 EF 32 E0 02 28
					19 01 1D 00 48 C9 05 E4
					89 80 C4 C4 05 03 12 1E
					5A 0F 0A 20 00 01 01 07
					04 04 0A C0 19 64 26 26
					80 80 00 00 1E 03 06 14
					28 10 40 10 04 04 2D 1C
					00 15 40 32 50 00 00 00
					00 4C 04 6C 07 3C 32 00
					00 00 00 4C 04 6C 07 1E
					05 1E 04 0A 04 0A 00 0A
					04 04 00 00 00 01 05 0A
					10 00 00 00 14 03 06 0F
					0A 00 4B 00 FF 00 04 01
					80 04 1B 00 00 00 64 00
					00 00 BE 4B 96 00 00 C0
					80 00 10 0A 18 00 7D 00
					02 00 00 90 01 02 00 06
					06 07 07 00 96 00 08 0C
					01 04 03 2A 00 13 00 00
					00 03 00 01 25 03 29 00
					12 00 02 00 03 00 01 27
					03 28 00 11 00 04 00 03
					00 01 28 02 26 00 11 00
					06 00 03 00 01 29 02 25
					00 10 00 08 00 07 00 02
					25 02 24 00 10 00 0A 00
					07 00 02 26 02 23 00 0F
					00 0C 00 07 00 02 27 02
					22 00 0F 00 0E 00 04 00
					01 23 0F 0F 0F 0F 0F 0F
					0F 0F 0F 0F 0F 0F 0F 0F
					0F 0F 00 00 00 00 00 00
					00 00 00 00 00 00 00 00
					00 00 00 00 00 00 00 00
					00 00 00 00 00 00 00 00
					00 00 00 00 00 00 00 00
					00 00 00 00 00 00 00 00
					00 00 00 00 00 00 00 00
					00 00 00 00 00 00 0E 0E
					02 00 04 0E 0E 02 00 04
					2B 00 05 00 A6 00 14 64
					05 04 04 03 03 04 04 03
					03 00 1B 28 05 01 00 22
					20 00 05 00 00 00 14 28
					28 A0 00 A0 00 00 00 00
					00 00 00 00 00 00 00 00
					00 00 FF FF FF FF FF FF
					FF FF 51 51 51 51 CD 0D
					04 83 10 10 10 10 05 1F
					1E 1D 1C 1B 1A 19 18 17
					16 15 14 13 12 11 FF FF
					FF FF FF FF FF 00 01 02
					03 04 05 06 07 08 09 0A
					0B 0C 0D 33 32 31 30 2F
					2E 2D 2C 2B 2A 29 28 27
					FF FF FF FF FF 00 10 00
					10 00 10 00 10 80 80 80
					80 80 80 80 80 80 80 80
					80 80 80 80 80 80 80 80
					80 80 80 80 80 80 80 80
					80 80 80 80 80 80 80 80
					80 80 80 80 80 80 80 80
					80 80 80 80 80 80 80 80
					80 80 80 00 10 00 10 00
					10 00 10 00 00 21 22 FF
					FF 0E 26 35 FF
				];
			};

			config_3508_0key_tsxm_2 {
				default_cfg   = <1>;
				pr_number     = <1543518>;
				sensor_id     = <0x4>;
				syn,pl-coords = <0 1620 0 2880>;
				vkey_setting  = <0>;
				config = [
					54 53 58 00 00 3F 03 1E
					05 0E 54 06 40 0B 4D 41
					48 3B 00 00 00 00 11 1B
					01 1E 05 EF 32 E0 02 28
					19 01 1D 00 48 C9 05 E4
					89 80 C4 C4 05 03 12 1E
					5A 0F 0A 20 00 01 01 07
					04 04 0A C0 19 64 26 26
					80 80 00 00 1E 03 06 14
					28 10 40 10 04 04 2D 1C
					00 15 40 32 50 00 00 00
					00 4C 04 6C 07 3C 32 00
					00 00 00 4C 04 6C 07 1E
					05 1E 04 0A 04 0A 00 0A
					04 04 00 00 00 01 05 0A
					10 00 00 00 14 03 06 0F
					0A 00 4B 00 FF 00 04 01
					80 04 1B 00 00 00 64 00
					00 00 BE 4B 96 00 00 C0
					80 00 10 0A 18 00 7D 00
					02 00 00 90 01 02 00 06
					06 07 07 00 96 00 08 0C
					01 04 03 2A 00 13 00 00
					00 03 00 01 25 03 29 00
					12 00 02 00 03 00 01 27
					03 28 00 11 00 04 00 03
					00 01 28 02 26 00 11 00
					06 00 03 00 01 29 02 25
					00 10 00 08 00 07 00 02
					25 02 24 00 10 00 0A 00
					07 00 02 26 02 23 00 0F
					00 0C 00 07 00 02 27 02
					22 00 0F 00 0E 00 04 00
					01 23 0F 0F 0F 0F 0F 0F
					0F 0F 0F 0F 0F 0F 0F 0F
					0F 0F 00 00 00 00 00 00
					00 00 00 00 00 00 00 00
					00 00 00 00 00 00 00 00
					00 00 00 00 00 00 00 00
					00 00 00 00 00 00 00 00
					00 00 00 00 00 00 00 00
					00 00 00 00 00 00 00 00
					00 00 00 00 00 00 0E 0E
					02 00 04 0E 0E 02 00 04
					2B 00 05 00 A6 00 14 64
					05 04 04 03 03 04 04 03
					03 00 1B 28 05 01 00 22
					20 00 05 00 00 00 14 28
					28 A0 00 A0 00 00 00 00
					00 00 00 00 00 00 00 00
					00 00 FF FF FF FF FF FF
					FF FF 51 51 51 51 CD 0D
					04 83 10 10 10 10 05 22
					21 20 1F 1E 1D 1C 1B 1A
					19 18 17 16 15 14 13 12
					FF FF FF FF FF 00 01 02
					03 04 05 06 07 08 09 0A
					0B 0C 0D 0E 26 33 32 31
					30 2F 2E 2D 2C 2B 2A 29
					FF FF FF FF FF 00 10 00
					10 00 10 00 10 80 80 80
					80 80 80 80 80 80 80 80
					80 80 80 80 80 80 80 80
					80 80 80 80 80 80 80 80
					80 80 80 80 80 80 80 80
					80 80 80 80 80 80 80 80
					80 80 80 80 80 80 80 80
					80 80 80 00 10 00 10 00
					10 00 10 00 00 FF FF FF
					FF FF FF FF FF
				];
			};

			config_3508_0key_tsms_2 {
				default_cfg   = <1>;
				pr_number     = <1543518>;
				sensor_id     = <0x5>;
				syn,pl-coords = <0 1620 0 2880>;
				vkey_setting  = <0>;
				config = [
					54 53 58 00 00 3F 03 1E
					05 0E 54 06 40 0B 4D 41
					48 3B 00 00 00 00 11 1B
					01 1E 05 EF 32 E0 02 28
					19 01 1D 00 48 C9 05 E4
					89 80 C4 C4 05 03 12 1E
					5A 0F 0A 20 00 01 01 07
					04 04 0A C0 19 64 26 26
					80 80 00 00 1E 03 06 14
					28 10 40 10 04 04 2D 1C
					00 15 40 32 50 00 00 00
					00 4C 04 6C 07 3C 32 00
					00 00 00 4C 04 6C 07 1E
					05 1E 04 0A 04 0A 00 0A
					04 04 00 00 00 01 05 0A
					10 00 00 00 14 03 06 0F
					0A 00 4B 00 FF 00 04 01
					80 04 1B 00 00 00 64 00
					00 00 BE 4B 96 00 00 C0
					80 00 10 0A 18 00 7D 00
					02 00 00 90 01 02 00 06
					06 07 07 00 96 00 08 0C
					01 04 03 2A 00 13 00 00
					00 03 00 01 25 03 29 00
					12 00 02 00 03 00 01 27
					03 28 00 11 00 04 00 03
					00 01 28 02 26 00 11 00
					06 00 03 00 01 29 02 25
					00 10 00 08 00 07 00 02
					25 02 24 00 10 00 0A 00
					07 00 02 26 02 23 00 0F
					00 0C 00 07 00 02 27 02
					22 00 0F 00 0E 00 04 00
					01 23 0F 0F 0F 0F 0F 0F
					0F 0F 0F 0F 0F 0F 0F 0F
					0F 0F 00 00 00 00 00 00
					00 00 00 00 00 00 00 00
					00 00 00 00 00 00 00 00
					00 00 00 00 00 00 00 00
					00 00 00 00 00 00 00 00
					00 00 00 00 00 00 00 00
					00 00 00 00 00 00 00 00
					00 00 00 00 00 00 0E 0E
					02 00 04 0E 0E 02 00 04
					2B 00 05 00 A6 00 14 64
					05 04 04 03 03 04 04 03
					03 00 1B 28 05 01 00 22
					20 00 05 00 00 00 14 28
					28 A0 00 A0 00 00 00 00
					00 00 00 00 00 00 00 00
					00 00 FF FF FF FF FF FF
					FF FF 51 51 51 51 CD 0D
					04 83 10 10 10 10 05 22
					21 20 1F 1E 1D 1C 1B 1A
					19 18 17 16 15 14 13 12
					FF FF FF FF FF 00 01 02
					03 04 05 06 07 08 09 0A
					0B 0C 0D 0E 26 33 32 31
					30 2F 2E 2D 2C 2B 2A 29
					FF FF FF FF FF 00 10 00
					10 00 10 00 10 80 80 80
					80 80 80 80 80 80 80 80
					80 80 80 80 80 80 80 80
					80 80 80 80 80 80 80 80
					80 80 80 80 80 80 80 80
					80 80 80 80 80 80 80 80
					80 80 80 80 80 80 80 80
					80 80 80 00 10 00 10 00
					10 00 10 00 00 FF FF FF
					FF FF FF FF FF
				];
			};

			config_3508_2key_metm_1 {
				default_cfg   = <1>;
				pr_number     = <1543518>;
				sensor_id     = <0x0>;
				syn,pl-coords = <0 1620 0 2880>;
				vkey_setting  = <0>;
				config = [
					4D 45 54 31 00 3F 03 1E
					05 0E 54 06 40 0B 23 43
					5A 41 00 00 00 00 0F 1B
					01 1E 05 EF 32 DD 02 50
					19 01 1D 00 48 C9 05 E4
					89 80 C4 C4 05 03 12 1E
					5A 0F 0A 20 00 01 01 07
					04 04 0A C0 19 64 26 26
					80 80 00 00 1E 03 06 14
					28 10 40 10 04 04 2D 1C
					00 15 40 32 50 32 00 00
					00 00 4C 04 6C 07 3C 32
					00 00 00 00 4C 04 6C 07
					1E 05 1E 04 0A 04 0A 00
					0A 04 04 00 00 00 01 05
					0A 00 00 00 4B FF 00 04
					01 80 04 1B 00 00 00 64
					00 00 00 BE 4B 96 00 00
					C0 80 00 10 0A 18 00 7D
					00 02 00 00 90 01 02 00
					06 06 07 07 00 96 00 08
					0C 01 04 03 29 00 13 00
					00 00 03 00 01 25 03 28
					00 12 00 02 00 03 00 01
					27 82 26 00 11 00 04 00
					03 00 01 28 02 25 00 11
					00 06 00 03 00 01 29 02
					24 00 10 00 08 00 07 00
					02 25 02 23 00 10 00 0A
					00 07 00 02 26 02 22 00
					0F 00 0C 00 07 00 02 27
					02 21 00 0F 00 0E 00 04
					00 01 23 0E 0F 0F 0F 0F
					0F 0E 0F 0F 0F 0F 0F 0F
					0F 0F 0F 0C 00 00 00 00
					00 00 00 00 00 00 00 00
					00 00 00 00 00 00 00 00
					00 00 00 00 00 00 00 00
					00 00 00 00 00 00 00 00
					00 00 00 00 00 00 00 00
					00 00 00 00 00 00 00 00
					00 00 00 00 00 00 00 0E
					0E 02 00 04 0E 0E 02 00
					04 2B 00 05 00 A6 00 14
					64 05 04 04 03 03 04 04
					03 03 00 1B 28 05 01 00
					22 20 00 05 00 00 00 14
					2D 2D A0 00 A0 00 00 00
					00 FF FF FF FF FF FF FF
					FF A1 A1 51 51 CD 0D 04
					83 10 10 10 10 05 1F 1E
					1D 1C 1B 1A 19 18 17 16
					15 14 13 12 11 FF FF FF
					FF FF FF FF 00 01 02 03
					04 05 06 07 08 09 0A 0B
					0C 0D 33 32 31 30 2F 2E
					2D 2C 2B 2A 29 28 27 FF
					FF FF FF FF 00 10 00 10
					00 10 00 10 80 80 80 80
					80 80 80 80 80 80 80 80
					80 80 80 80 80 80 80 80
					80 80 80 80 80 80 80 80
					80 80 80 80 80 80 80 80
					80 80 80 80 80 80 80 80
					80 80 80 80 80 80 80 80
					80 80 00 10 00 10 00 10
					00 10
				];
			};

			config_3508_2key_mets_1 {
				default_cfg   = <1>;
				pr_number     = <1543518>;
				sensor_id     = <0x1>;
				syn,pl-coords = <0 1620 0 2880>;
				vkey_setting  = <0>;
				config = [
					4D 45 54 31 00 3F 03 1E
					05 0E 54 06 40 0B 23 43
					5A 41 00 00 00 00 0F 1B
					01 1E 05 EF 32 DD 02 50
					19 01 1D 00 48 C9 05 E4
					89 80 C4 C4 05 03 12 1E
					5A 0F 0A 20 00 01 01 07
					04 04 0A C0 19 64 26 26
					80 80 00 00 1E 03 06 14
					28 10 40 10 04 04 2D 1C
					00 15 40 32 50 32 00 00
					00 00 4C 04 6C 07 3C 32
					00 00 00 00 4C 04 6C 07
					1E 05 1E 04 0A 04 0A 00
					0A 04 04 00 00 00 01 05
					0A 00 00 00 4B FF 00 04
					01 80 04 1B 00 00 00 64
					00 00 00 BE 4B 96 00 00
					C0 80 00 10 0A 18 00 7D
					00 02 00 00 90 01 02 00
					06 06 07 07 00 96 00 08
					0C 01 04 03 29 00 13 00
					00 00 03 00 01 25 03 28
					00 12 00 02 00 03 00 01
					27 82 26 00 11 00 04 00
					03 00 01 28 02 25 00 11
					00 06 00 03 00 01 29 02
					24 00 10 00 08 00 07 00
					02 25 02 23 00 10 00 0A
					00 07 00 02 26 02 22 00
					0F 00 0C 00 07 00 02 27
					02 21 00 0F 00 0E 00 04
					00 01 23 0E 0F 0F 0F 0F
					0F 0E 0F 0F 0F 0F 0F 0F
					0F 0F 0F 0C 00 00 00 00
					00 00 00 00 00 00 00 00
					00 00 00 00 00 00 00 00
					00 00 00 00 00 00 00 00
					00 00 00 00 00 00 00 00
					00 00 00 00 00 00 00 00
					00 00 00 00 00 00 00 00
					00 00 00 00 00 00 00 0E
					0E 02 00 04 0E 0E 02 00
					04 2B 00 05 00 A6 00 14
					64 05 04 04 03 03 04 04
					03 03 00 1B 28 05 01 00
					22 20 00 05 00 00 00 14
					2D 2D A0 00 A0 00 00 00
					00 FF FF FF FF FF FF FF
					FF A1 A1 51 51 CD 0D 04
					83 10 10 10 10 05 1F 1E
					1D 1C 1B 1A 19 18 17 16
					15 14 13 12 11 FF FF FF
					FF FF FF FF 00 01 02 03
					04 05 06 07 08 09 0A 0B
					0C 0D 33 32 31 30 2F 2E
					2D 2C 2B 2A 29 28 27 FF
					FF FF FF FF 00 10 00 10
					00 10 00 10 80 80 80 80
					80 80 80 80 80 80 80 80
					80 80 80 80 80 80 80 80
					80 80 80 80 80 80 80 80
					80 80 80 80 80 80 80 80
					80 80 80 80 80 80 80 80
					80 80 80 80 80 80 80 80
					80 80 00 10 00 10 00 10
					00 10
				];
			};

			config_3508_0key_tsxm_1 {
				default_cfg   = <1>;
				pr_number     = <1543518>;
				sensor_id     = <0x4>;
				syn,pl-coords = <0 1620 0 2880>;
				vkey_setting  = <0>;
				config = [
					54 53 58 31 00 3F 03 1E
					05 0E 54 06 40 0B 48 3B
					66 41 00 00 00 00 11 1B
					01 1E 05 EF 32 DD 02 50
					19 01 1D 00 48 C9 05 E4
					89 80 C4 C4 05 03 12 1E
					5A 0F 0A 20 00 01 01 07
					04 04 0A C0 19 64 26 26
					80 80 00 00 1E 03 06 14
					28 10 40 10 04 04 2D 1C
					00 15 40 32 50 32 00 00
					00 00 4C 04 6C 07 3C 32
					00 00 00 00 4C 04 6C 07
					1E 05 1E 04 0A 04 0A 00
					0A 04 04 00 00 00 01 05
					0A 00 00 00 4B FF 00 04
					01 80 04 1B 00 00 00 64
					00 00 00 BE 4B 96 00 00
					C0 80 00 10 0A 18 00 7D
					00 02 00 00 90 01 02 00
					06 06 07 07 00 96 00 08
					0C 01 04 03 29 00 13 00
					00 00 03 00 01 25 03 28
					00 12 00 02 00 03 00 01
					27 82 26 00 11 00 04 00
					03 00 01 28 02 25 00 11
					00 06 00 03 00 01 29 02
					24 00 10 00 08 00 07 00
					02 25 02 23 00 10 00 0A
					00 07 00 02 26 02 22 00
					0F 00 0C 00 07 00 02 27
					02 21 00 0F 00 0E 00 04
					00 01 23 0E 0F 0F 0F 0F
					0F 0E 0F 0F 0F 0F 0F 0F
					0F 0F 0F 0C 00 00 00 00
					00 00 00 00 00 00 00 00
					00 00 00 00 00 00 00 00
					00 00 00 00 00 00 00 00
					00 00 00 00 00 00 00 00
					00 00 00 00 00 00 00 00
					00 00 00 00 00 00 00 00
					00 00 00 00 00 00 00 0E
					0E 02 00 04 0E 0E 02 00
					04 2B 00 05 00 A6 00 14
					64 05 04 04 03 03 04 04
					03 03 00 1B 28 05 01 00
					22 20 00 05 00 00 00 14
					2D 2D A0 00 A0 00 00 00
					00 FF FF FF FF FF FF FF
					FF A1 A1 51 51 CD 0D 04
					83 10 10 10 10 05 22 21
					20 1F 1E 1D 1C 1B 1A 19
					18 17 16 15 14 13 12 FF
					FF FF FF FF 00 01 02 03
					04 05 06 07 08 09 0A 0B
					0C 0D 0E 26 33 32 31 30
					2F 2E 2D 2C 2B 2A 29 FF
					FF FF FF FF 00 10 00 10
					00 10 00 10 80 80 80 80
					80 80 80 80 80 80 80 80
					80 80 80 80 80 80 80 80
					80 80 80 80 80 80 80 80
					80 80 80 80 80 80 80 80
					80 80 80 80 80 80 80 80
					80 80 80 80 80 80 80 80
					80 80 00 10 00 10 00 10
					00 10
				];
			};

			config_3508_0key_tsms_1 {
				default_cfg   = <1>;
				pr_number     = <1543518>;
				sensor_id     = <0x5>;
				syn,pl-coords = <0 1620 0 2880>;
				vkey_setting  = <0>;
				config = [
					54 53 58 31 00 3F 03 1E
					05 0E 54 06 40 0B 48 3B
					66 41 00 00 00 00 11 1B
					01 1E 05 EF 32 DD 02 50
					19 01 1D 00 48 C9 05 E4
					89 80 C4 C4 05 03 12 1E
					5A 0F 0A 20 00 01 01 07
					04 04 0A C0 19 64 26 26
					80 80 00 00 1E 03 06 14
					28 10 40 10 04 04 2D 1C
					00 15 40 32 50 32 00 00
					00 00 4C 04 6C 07 3C 32
					00 00 00 00 4C 04 6C 07
					1E 05 1E 04 0A 04 0A 00
					0A 04 04 00 00 00 01 05
					0A 00 00 00 4B FF 00 04
					01 80 04 1B 00 00 00 64
					00 00 00 BE 4B 96 00 00
					C0 80 00 10 0A 18 00 7D
					00 02 00 00 90 01 02 00
					06 06 07 07 00 96 00 08
					0C 01 04 03 29 00 13 00
					00 00 03 00 01 25 03 28
					00 12 00 02 00 03 00 01
					27 82 26 00 11 00 04 00
					03 00 01 28 02 25 00 11
					00 06 00 03 00 01 29 02
					24 00 10 00 08 00 07 00
					02 25 02 23 00 10 00 0A
					00 07 00 02 26 02 22 00
					0F 00 0C 00 07 00 02 27
					02 21 00 0F 00 0E 00 04
					00 01 23 0E 0F 0F 0F 0F
					0F 0E 0F 0F 0F 0F 0F 0F
					0F 0F 0F 0C 00 00 00 00
					00 00 00 00 00 00 00 00
					00 00 00 00 00 00 00 00
					00 00 00 00 00 00 00 00
					00 00 00 00 00 00 00 00
					00 00 00 00 00 00 00 00
					00 00 00 00 00 00 00 00
					00 00 00 00 00 00 00 0E
					0E 02 00 04 0E 0E 02 00
					04 2B 00 05 00 A6 00 14
					64 05 04 04 03 03 04 04
					03 03 00 1B 28 05 01 00
					22 20 00 05 00 00 00 14
					2D 2D A0 00 A0 00 00 00
					00 FF FF FF FF FF FF FF
					FF A1 A1 51 51 CD 0D 04
					83 10 10 10 10 05 22 21
					20 1F 1E 1D 1C 1B 1A 19
					18 17 16 15 14 13 12 FF
					FF FF FF FF 00 01 02 03
					04 05 06 07 08 09 0A 0B
					0C 0D 0E 26 33 32 31 30
					2F 2E 2D 2C 2B 2A 29 FF
					FF FF FF FF 00 10 00 10
					00 10 00 10 80 80 80 80
					80 80 80 80 80 80 80 80
					80 80 80 80 80 80 80 80
					80 80 80 80 80 80 80 80
					80 80 80 80 80 80 80 80
					80 80 80 80 80 80 80 80
					80 80 80 80 80 80 80 80
					80 80 00 10 00 10 00 10
					00 10
				];
			};

			config_t6m_1 {
				default_cfg   = <1>;
				pr_number     = <1501819>;
				sensor_id     = <0x04>;
				syn,pl-coords = <50 1050 0 1800>;
				vkey_setting  = <2>;
				config = [
					00 00 00 02 04 3F 03 1E
					05 0E 4C 04 6C 07 00 40
					00 40 00 00 00 00 11 1D
					01 1E 05 F5 28 1E 05 28
					30 00 30 00 F0 D2 F0 D2
					89 80 C4 C4 05 03 05 0F
					80 0F 0A 20 00 01 01 07
					04 04 0A C0 19 64 26 26
					80 80 00 00 80 19 01 40
					40 32 50 80 32 00 00 00
					00 4C 04 6C 07 3C 32 00
					00 00 00 4C 04 6C 07 1E
					05 00 00 00 00 05 0A 00
					03 FF 00 FA 00 80 04 1B
					00 00 00 FF FF FF FF FF
					FF FF FF 00 C0 80 00 10
					0A 18 00 71 00 FF FF 00
					FF FF FF FF 03 03 07 07
					01 FF FF 01 04 05 4A 00
					4A 00 00 00 02 00 01 3E
					85 4A 00 4A 00 00 00 02
					00 01 3E 85 4A 00 4A 00
					00 00 02 00 01 3E 85 4A
					00 4A 00 00 00 02 00 01
					3E 85 4A 00 4A 00 00 00
					02 00 01 3E 85 4A 00 4A
					00 00 00 02 00 01 3E 85
					4A 00 4A 00 00 00 02 00
					01 3E 85 4A 00 4A 00 00
					00 02 00 01 3E 02 02 02
					02 02 02 02 02 02 02 02
					02 02 02 02 02 02 02 02
					02 02 02 26 00 05 00 A6
					00 14 64 05 00 1B 00 11
					0A 32 0A 32 14 20 46 00
					00 00 FF FF FF FF FF FF
					FF FF 51 51 51 51 CD 0D
					04 83 10 10 10 10 05 22
					21 20 1F 1E 1D 1C 1B 1A
					19 18 17 16 15 14 13 12
					FF FF FF FF FF 00 01 02
					03 04 05 06 07 08 09 0A
					0B 0C 0D 0E 26 33 32 31
					30 2F 2E 2D 2C 2B 2A 29
					28 27 FF FF FF 00 10 00
					10 00 10 00 10 80 80 80
					80 80 80 80 80 80 80 80
					80 80 80 80 80 80 80 80
					80 80 80 80 80 80 80 80
					80 80 80 80 80 80 80 80
					80 80 80 80 80 80 80 80
					80 80 80 80 80 80 80 80
					80 80 80 00 10 00 10 00
					10 00 10
				];
			};

			config_t6s_1 {
				default_cfg   = <1>;
				pr_number     = <1501819>;
				sensor_id     = <0x05>;
				syn,pl-coords = <50 1050 0 1800>;
				vkey_setting  = <2>;
				config = [
					00 00 00 02 04 3F 03 1E
					05 0E 4C 04 6C 07 00 40
					00 40 00 00 00 00 11 1D
					01 1E 05 F5 28 1E 05 28
					30 00 30 00 F0 D2 F0 D2
					89 80 C4 C4 05 03 05 0F
					80 0F 0A 20 00 01 01 07
					04 04 0A C0 19 64 26 26
					80 80 00 00 80 19 01 40
					40 32 50 80 32 00 00 00
					00 4C 04 6C 07 3C 32 00
					00 00 00 4C 04 6C 07 1E
					05 00 00 00 00 05 0A 00
					03 FF 00 FA 00 80 04 1B
					00 00 00 FF FF FF FF FF
					FF FF FF 00 C0 80 00 10
					0A 18 00 71 00 FF FF 00
					FF FF FF FF 03 03 07 07
					01 FF FF 01 04 05 4A 00
					4A 00 00 00 02 00 01 3E
					85 4A 00 4A 00 00 00 02
					00 01 3E 85 4A 00 4A 00
					00 00 02 00 01 3E 85 4A
					00 4A 00 00 00 02 00 01
					3E 85 4A 00 4A 00 00 00
					02 00 01 3E 85 4A 00 4A
					00 00 00 02 00 01 3E 85
					4A 00 4A 00 00 00 02 00
					01 3E 85 4A 00 4A 00 00
					00 02 00 01 3E 02 02 02
					02 02 02 02 02 02 02 02
					02 02 02 02 02 02 02 02
					02 02 02 26 00 05 00 A6
					00 14 64 05 00 1B 00 11
					0A 32 0A 32 14 20 46 00
					00 00 FF FF FF FF FF FF
					FF FF 51 51 51 51 CD 0D
					04 83 10 10 10 10 05 22
					21 20 1F 1E 1D 1C 1B 1A
					19 18 17 16 15 14 13 12
					FF FF FF FF FF 00 01 02
					03 04 05 06 07 08 09 0A
					0B 0C 0D 0E 26 33 32 31
					30 2F 2E 2D 2C 2B 2A 29
					28 27 FF FF FF 00 10 00
					10 00 10 00 10 80 80 80
					80 80 80 80 80 80 80 80
					80 80 80 80 80 80 80 80
					80 80 80 80 80 80 80 80
					80 80 80 80 80 80 80 80
					80 80 80 80 80 80 80 80
					80 80 80 80 80 80 80 80
					80 80 80 00 10 00 10 00
					10 00 10
				];
			};
		};

	};
};
